# CH32V00Xxx register map
Vendor: WCH Ltd.; File version: 1.0
Registers are 32-bit, read-write, reset 0x0 unless marked. A register's access mark holds for its fields unless they carry their own. Offsets are from the block's base; [hi:lo] are bit positions.

## SPI1 — Serial peripheral interface
Base 0x40013000
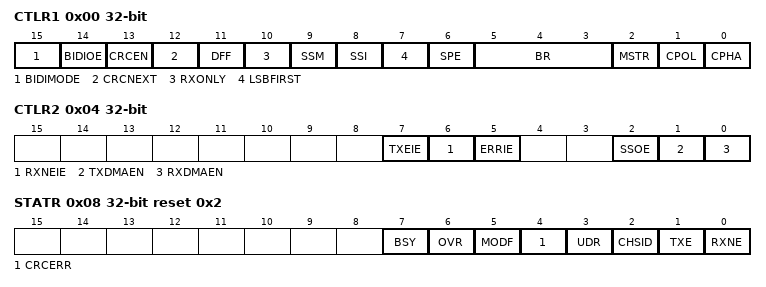
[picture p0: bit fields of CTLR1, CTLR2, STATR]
0x00 CTLR1 — control register 1
  [15] BIDIMODE — Bidirectional data mode enable
  [14] BIDIOE — Output enable in bidirectional mode
  [13] CRCEN — Hardware CRC calculation enable
  [12] CRCNEXT — CRC transfer next
  [11] DFF — Data frame format
  [10] RXONLY — Receive only
  [9] SSM — Software slave management
  [8] SSI — Internal slave select
  [7] LSBFIRST — Frame format
  [6] SPE — SPI enable
  [5:3] BR — Baud rate control
  [2] MSTR — Master selection
  [1] CPOL — Clock polarity
  [0] CPHA — Clock phase
0x04 CTLR2 — control register 2
  [7] TXEIE — Tx buffer empty interrupt enable
  [6] RXNEIE — RX buffer not empty interrupt enable
  [5] ERRIE — Error interrupt enable
  [2] SSOE — SS output enable
  [1] TXDMAEN — Tx buffer DMA enable
  [0] RXDMAEN — Rx buffer DMA enable
0x08 STATR access per field reset 0x2 — status register
  [7] BSY ro — Busy flag
  [6] OVR rw — Overrun flag
  [5] MODF ro — Mode fault
  [4] CRCERR rw — CRC error flag
  [3] UDR ro — Underrun flag
  [2] CHSID ro — Channel side
  [1] TXE ro — Transmit buffer empty
  [0] RXNE ro — Receive buffer not empty
0x0C DATAR — data register
  [15:0] DR — Data register
0x10 CRCR reset 0x7 — CRCR polynomial register
  [15:0] CRCPOLY — CRC polynomial register
0x14 RCRCR ro — RX CRC register
  [15:0] RXCRC
0x18 TCRCR ro — send CRC register
  [15:0] TXCRC
0x24 HSCR wo — high speed control register
  [0] HSRXEN — High speed mode read enable

## OPA — OPA and CMP
Base 0x40024000
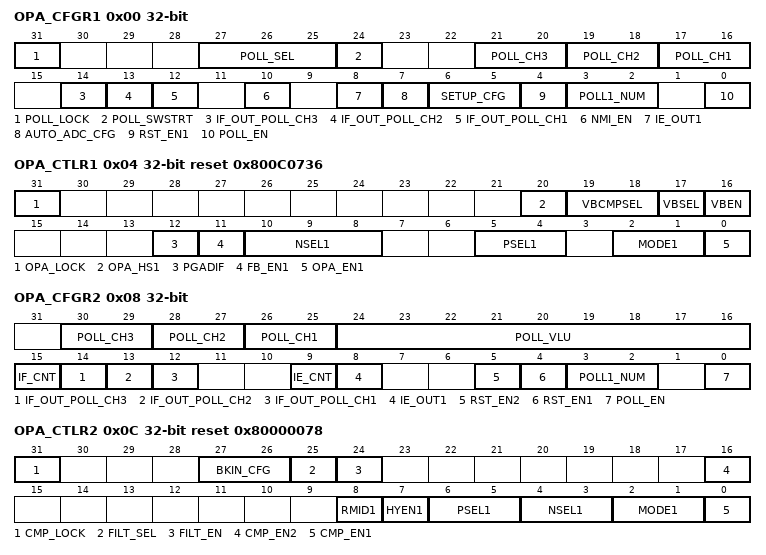
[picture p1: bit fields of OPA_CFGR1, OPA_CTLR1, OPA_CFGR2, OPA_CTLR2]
0x00 OPA_CFGR1 access per field — OPA configuration register
  [31] POLL_LOCK ro
  [27:25] POLL_SEL rw — POLL polling trigger events selection
  [24] POLL_SWSTRT wo — Start POLL polling
  [21:20] POLL_CH3 rw — POLL polling trigger events selection
  [19:18] POLL_CH2 rw — POLL polling trigger events selection
  [17:16] POLL_CH1 rw — POLL polling trigger events selection
  [14] IF_OUT_POLL_CH3 rw — Interrupt flag is polled until the OPA1 output is high
  [13] IF_OUT_POLL_CH2 rw — Interrupt flag is polled until the OPA1 output is high
  [12] IF_OUT_POLL_CH1 rw — Interrupt flag is polled until the OPA1 output is high
  [10] NMI_EN rw — OPA connection NMI interrupt enabled
  [8] IE_OUT1 rw — OPA1 interrupt enable
  [7] AUTO_ADC_CFG rw — OPA automatically polls
  [6:5] SETUP_CFG rw — OPA establishes the time configuration
  [4] RST_EN1 rw — OPA1 reset system enable
  [3:2] POLL1_NUM rw — configure the number of positive for OPA1 polling
  [0] POLL_EN rw — OPA1 positive end is enable by polling
0x04 OPA_CTLR1 reset 0x800C0736 — OPA control register
  [31] OPA_LOCK
  [20] OPA_HS1 — OPA1 high-speed mode enabled
  [19:18] VBCMPSEL — Reference voltage at the negative end of CMP2 is given
  [17] VBSEL — Reference voltage selection at the positive end in PGA mode
  [16] VBEN — Positive terminal reference voltage is enable in PGA mode
  [12] PGADIF — Linked switch
  [11] FB_EN1 — OPA1 is enable by internal feedback resistor
  [10:8] NSEL1 — OPA1 minus end input channel and gain selection when used as PGA
  [5:4] PSEL1 — OPA1 positive input channel selection
  [2:1] MODE1 — OPA1 output channel selection
  [0] OPA_EN1 — OPA1 enable
0x08 OPA_CFGR2 — CMP configuration register
  [30:29] POLL_CH3 — POLL polling trigger events selection
  [28:27] POLL_CH2 — POLL polling trigger events selection
  [26:25] POLL_CH1 — POLL polling trigger events selection
  [24:16] POLL_VLU — Configure CMP1 positive end polling interval
  [15] IF_CNT — Interrupt flag at end of polling interval for CMP1
  [14] IF_OUT_POLL_CH3 — Interrupt flag is polled until the CMP1 output is high
  [13] IF_OUT_POLL_CH2 — Interrupt flag is polled until the CMP1 output is high
  [12] IF_OUT_POLL_CH1 — Interrupt flag is polled until the CMP1 output is high
  [9] IE_CNT — Interrupt at end of CMP1 polling interval is enabled
  [8] IE_OUT1 — CMP1 interrupt enable
  [5] RST_EN2 — CMP2 reset system enable
  [4] RST_EN1 — CMP1 reset system enable
  [3:2] POLL1_NUM — configure the number of positive for CMP1 polling
  [0] POLL_EN — CMP1 positive end is enable by polling
0x0C OPA_CTLR2 reset 0x80000078 — OPA configuration register 2
  [31] CMP_LOCK
  [27:26] BKIN_CFG — TIM1 break source configuration
  [25] FILT_SEL — CMP output digital filter length selection
  [24] FILT_EN — CMP digital filter enable
  [16] CMP_EN2 — CMP2 enable
  [8] RMID1 — CMP1 positive input channel virtual center point enable
  [7] HYEN1 — CMP1 hysteresis comparator switch
  [6:5] PSEL1 — Input channel selection at the positive end of CMP1
  [4:3] NSEL1 — Input channel selection at the negative end of CMP1
  [2:1] MODE1 — CMP1 output mode selection
  [0] CMP_EN1 — CMP1 enable
0x10 OPA_KEY wo — OPA unlock key register
  [31:0] OPA_KEY — OPA_KEY value
0x14 CMP_KEY wo — CMP unlock key register
  [31:0] CMP_KEY — CMP_KEY value
0x18 POLL_KEY wo — POLL unlock key register
  [31:0] POLL_KEY — POLL_KEY value
